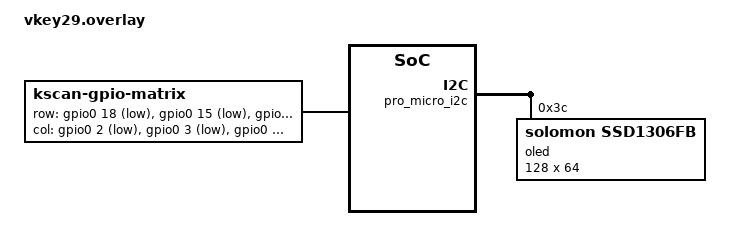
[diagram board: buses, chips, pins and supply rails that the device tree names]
/ {
    chosen {
        zmk,kscan = &kscan0;
        /* The chosen display must point to the node inside i2c */
        zmk,display = &oled;
    };

    kscan0: kscan {
        compatible = "zmk,kscan-gpio-matrix";
        label = "KSCAN";
        diode-direction = "col2row";

        row-gpios = <
            &gpio0 18 (GPIO_ACTIVE_LOW | GPIO_PULL_UP)
            &gpio0 15 (GPIO_ACTIVE_LOW | GPIO_PULL_UP)
            &gpio0 14 (GPIO_ACTIVE_LOW | GPIO_PULL_UP)
            &gpio0 16 (GPIO_ACTIVE_LOW | GPIO_PULL_UP)
            &gpio0 10 (GPIO_ACTIVE_LOW | GPIO_PULL_UP)
        >;

        col-gpios = <
            &gpio0 2  (GPIO_ACTIVE_LOW | GPIO_PULL_UP)
            &gpio0 3  (GPIO_ACTIVE_LOW | GPIO_PULL_UP)
            &gpio0 7  (GPIO_ACTIVE_LOW | GPIO_PULL_UP)
            &gpio0 6  (GPIO_ACTIVE_LOW | GPIO_PULL_UP)
            &gpio0 5  (GPIO_ACTIVE_LOW | GPIO_PULL_UP)
            &gpio0 4  (GPIO_ACTIVE_LOW | GPIO_PULL_UP)
            &gpio0 8  (GPIO_ACTIVE_LOW | GPIO_PULL_UP)
        >;
    };
};

/* Use pro_micro_i2c to use the default nice!nano SDA/SCL pins */
&pro_micro_i2c {
    status = "okay";

    oled: oled@3c {
        compatible = "solomon,ssd1306fb";
        reg = <0x3c>;
        width = <128>;
        height = <64>;
        segment-offset = <0>;
        page-offset = <0>;
        display-offset = <0>;
        multiplex-ratio = <63>;
        segment-remap;
        com-invdir;
        com-sequential;
        prechargep = <0x22>;
    };

};
